VERSION ""

NS_ :

BS_:

BU_: ECM VCU

BO_ 256 EngineData: 8 ECM
 SG_ EngineSpeed : 16|16@1+ (0.125,0) [0|8000] "rpm"  VCU
 SG_ CoolantTemp : 8|8@1+ (1,-40) [-40|215] "degC"  VCU
 SG_ Gear : 24|3@1+ (1,0) [0|7] ""  VCU

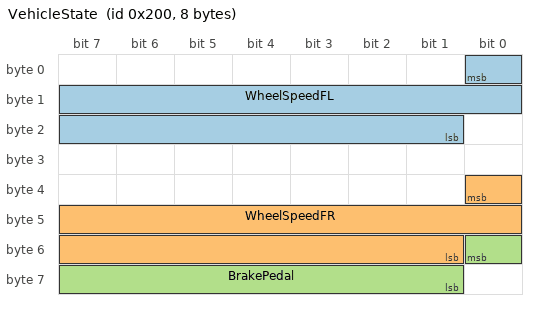
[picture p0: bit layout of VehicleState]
BO_ 512 VehicleState: 8 VCU
 SG_ WheelSpeedFL : 0|16@0+ (0.01,0) [0|655] "km/h"  ECM
 SG_ WheelSpeedFR : 32|16@0+ (0.01,0) [0|655] "km/h"  ECM
 SG_ BrakePedal : 48|8@0+ (0.5,0) [0|100] "%"  ECM
